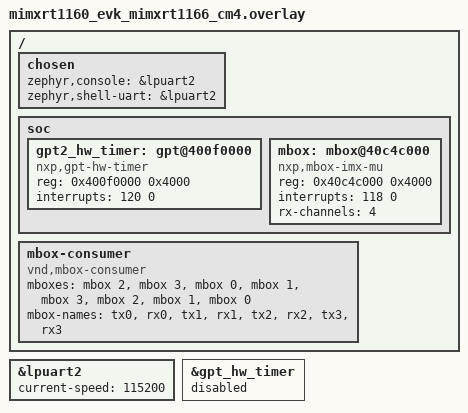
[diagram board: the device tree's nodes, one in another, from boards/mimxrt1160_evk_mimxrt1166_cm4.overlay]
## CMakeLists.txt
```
# Copyright 2024 NXP
#
# SPDX-License-Identifier: Apache-2.0
#

cmake_minimum_required(VERSION 3.28.0)

find_package(Zephyr REQUIRED HINTS $ENV{ZEPHYR_BASE})

project(mbox_data_ipc_remote)

target_sources(app PRIVATE src/main.c)
```

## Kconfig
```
# Copyright 2025 Analog Devices, Inc
#
# SPDX-License-Identifier: Apache-2.0

source "Kconfig.zephyr"

config CHANNELS_TO_TEST
	int "Number of mbox TX/RX channel pairs to test"
	default 4
	help
	  The number of TX/RX channel pairs that should be exercised by
	  this test. This should match the number of pairs set in the
	  devicetree.
```

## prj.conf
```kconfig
CONFIG_STDOUT_CONSOLE=n
CONFIG_MBOX=y
# CONFIG_NO_OPTIMIZATIONS=y
```

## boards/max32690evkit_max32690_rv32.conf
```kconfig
# Copyright (c) 2025 Analog Devices, Inc.
# SPDX-License-Identifier: Apache-2.0

CONFIG_CHANNELS_TO_TEST=1
```

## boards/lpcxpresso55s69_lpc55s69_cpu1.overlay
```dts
/*
 * Copyright 2024 NXP
 *
 * SPDX-License-Identifier: Apache-2.0
 */

/ {
	chosen {
		/* Delete ipc chosen property where old IPM mailbox driver below is
		 * configured.
		 */
		/delete-property/ zephyr,ipc;
	};

	soc {
		/* Delete IPM Driver node nxp,lpc-mailbox */
		/delete-node/ mailbox@8b000;

		/* Attach MBOX driver to Mailbox Unit */
		mbox: mbox@5008b000 {
			compatible = "nxp,mbox-mailbox";
			reg = <0x5008b000 0xec>;
			interrupts = <31 0>;
			rx-channels = <4>;
			#mbox-cells = <1>;
			status = "okay";
		};
	};

	mbox-consumer {
		compatible = "vnd,mbox-consumer";
		mboxes = <&mbox 2>, <&mbox 3>, <&mbox 0>, <&mbox 1>, <&mbox 3>,
			 <&mbox 2>, <&mbox 1>, <&mbox 0>;
		mbox-names = "tx0", "rx0", "tx1", "rx1", "tx2", "rx2", "tx3",
			     "rx3";
	};
};
```

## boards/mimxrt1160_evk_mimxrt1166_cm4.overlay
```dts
/*
 * Copyright 2024 NXP
 *
 * SPDX-License-Identifier: Apache-2.0
 */

/ {
	chosen {
		zephyr,console = &lpuart2;
		zephyr,shell-uart = &lpuart2;

		/* Delete ipc chosen property where old IPM mailbox driver below is
		 * configured.
		 */
		/delete-property/ zephyr,ipc;
	};

	soc {
		/delete-node/ gpt@400f0000;

		/* Replace GPT2 with another GPT kernel timer */
		gpt2_hw_timer: gpt@400f0000 {
			compatible = "nxp,gpt-hw-timer";
			reg = <0x400f0000 0x4000>;
			interrupts = <120 0>;
			status = "okay";
		};

		/* Delete IPM Driver node nxp,imx-mu */
		/delete-node/ mailbox@40c4c000;

		/* Attach MBOX driver to MU Unit */
		mbox: mbox@40c4c000 {
			compatible = "nxp,mbox-imx-mu";
			reg = <0x40c4c000 0x4000>;
			interrupts = <118 0>;
			rx-channels = <4>;
			#mbox-cells = <1>;
			status = "okay";
		};
	};

	mbox-consumer {
		compatible = "vnd,mbox-consumer";
		mboxes = <&mbox 2>, <&mbox 3>, <&mbox 0>, <&mbox 1>, <&mbox 3>,
			 <&mbox 2>, <&mbox 1>, <&mbox 0>;
		mbox-names = "tx0", "rx0", "tx1", "rx1", "tx2", "rx2", "tx3",
			     "rx3";
	};
};

/* Enable secondary LPUART */
&lpuart2 {
	status = "okay";
	current-speed = <115200>;
};

/* Disable primary GPT timer */
&gpt_hw_timer {
	status = "disabled";
};
```

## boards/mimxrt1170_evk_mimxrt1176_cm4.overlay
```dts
/*
 * Copyright 2024 NXP
 *
 * SPDX-License-Identifier: Apache-2.0
 */

/ {
	chosen {
		zephyr,console = &lpuart2;
		zephyr,shell-uart = &lpuart2;

		/* Delete ipc chosen property where old IPM mailbox driver below is
		 * configured.
		 */
		/delete-property/ zephyr,ipc;
	};

	soc {
		/delete-node/ gpt@400f0000;

		/* Replace GPT2 with another GPT kernel timer */
		gpt2_hw_timer: gpt@400f0000 {
			compatible = "nxp,gpt-hw-timer";
			reg = <0x400f0000 0x4000>;
			interrupts = <120 0>;
			status = "okay";
		};

		/* Delete IPM Driver node nxp,imx-mu */
		/delete-node/ mailbox@40c4c000;

		/* Attach MBOX driver to MU Unit */
		mbox: mbox@40c4c000 {
			compatible = "nxp,mbox-imx-mu";
			reg = <0x40c4c000 0x4000>;
			interrupts = <118 0>;
			rx-channels = <4>;
			#mbox-cells = <1>;
			status = "okay";
		};
	};

	mbox-consumer {
		compatible = "vnd,mbox-consumer";
		mboxes = <&mbox 2>, <&mbox 3>, <&mbox 0>, <&mbox 1>, <&mbox 3>,
			 <&mbox 2>, <&mbox 1>, <&mbox 0>;
		mbox-names = "tx0", "rx0", "tx1", "rx1", "tx2", "rx2", "tx3",
			     "rx3";
	};
};

/* Enable secondary LPUART */
&lpuart2 {
	current-speed = <115200>;
	status = "okay";
};

/* Disable primary GPT timer */
&gpt_hw_timer {
	status = "disabled";
};
```

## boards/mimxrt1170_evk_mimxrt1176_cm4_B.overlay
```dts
/*
 * Copyright 2024 NXP
 *
 * SPDX-License-Identifier: Apache-2.0
 */

/ {
	chosen {
		zephyr,console = &lpuart2;
		zephyr,shell-uart = &lpuart2;

		/* Delete ipc chosen property where old IPM mailbox driver below is
		 * configured.
		 */
		/delete-property/ zephyr,ipc;
	};

	soc {
		/delete-node/ gpt@400f0000;

		/* Replace GPT2 with another GPT kernel timer */
		gpt2_hw_timer:gpt@400f0000 {
			compatible = "nxp,gpt-hw-timer";
			reg = <0x400f0000 0x4000>;
			interrupts = <120 0>;
			status = "okay";
		};

		/* Delete IPM Driver node nxp,imx-mu */
		/delete-node/ mailbox@40c4c000;

		/* Attach MBOX driver to MU Unit */
		mbox:mbox@40c4c000 {
			compatible = "nxp,mbox-imx-mu";
			reg = <0x40c4c000 0x4000>;
			interrupts = <118 0>;
			rx-channels = <4>;
			#mbox-cells = <1>;
			status = "okay";
		};
	};

	mbox-consumer {
		compatible = "vnd,mbox-consumer";
		mboxes = <&mbox 2>, <&mbox 3>, <&mbox 0>, <&mbox 1>, <&mbox 3>,
			 <&mbox 2>, <&mbox 1>, <&mbox 0>;
		mbox-names = "tx0", "rx0", "tx1", "rx1", "tx2", "rx2", "tx3",
			     "rx3";
	};
};

/* Enable secondary LPUART */
&lpuart2 {
	status = "okay";
	current-speed = <115200>;
};

/* Disable primary GPT timer */
&gpt_hw_timer {
	status = "disabled";
};
```

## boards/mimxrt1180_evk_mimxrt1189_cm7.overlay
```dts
/*
 * Copyright 2025 NXP
 *
 * SPDX-License-Identifier: Apache-2.0
 */

/ {
	mbox-consumer {
		compatible = "vnd,mbox-consumer";
		mboxes = <&mbox1_b 2>, <&mbox1_b 3>, <&mbox1_b 0>, <&mbox1_b 1>, <&mbox1_b 3>,
			 <&mbox1_b 2>, <&mbox1_b 1>, <&mbox1_b 0>;
		mbox-names = "tx0", "rx0", "tx1", "rx1", "tx2", "rx2", "tx3",
			     "rx3";
	};
};
```

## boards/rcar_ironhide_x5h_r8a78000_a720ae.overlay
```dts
/*
 * Copyright 2026 BayLibre, SAS
 *
 * SPDX-License-Identifier: Apache-2.0
 */

/ {
	mbox-consumer {
		compatible = "vnd,mbox-consumer";
		mboxes = <&mfis 0>, <&mfis 0>,
			 <&mfis 1>, <&mfis 1>,
			 <&mfis 2>, <&mfis 2>,
			 <&mfis 3>, <&mfis 3>;
		mbox-names = "tx0", "rx0",
			     "tx1", "rx1",
			     "tx2", "rx2",
			     "tx3", "rx3";
	};
};
```

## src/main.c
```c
/*
 * Copyright 2024 NXP
 *
 * SPDX-License-Identifier: Apache-2.0
 */

#include <stdio.h>
#include <stdlib.h>
#include <string.h>
#include <zephyr/kernel.h>
#include <zephyr/drivers/mbox.h>

static K_SEM_DEFINE(g_mbox_data_rx_sem, 0, 1);

static uint64_t g_mbox_received_data;
static uint32_t g_mbox_received_channel;

#define TX_CHANNEL_INDEX 0
#define RX_CHANNEL_INDEX 1

#if DT_HAS_COMPAT_STATUS_OKAY(zephyr_mbox_consumer)
#define MBOX_CONSUMER_NODE DT_COMPAT_GET_ANY_STATUS_OKAY(zephyr_mbox_consumer)
#elif DT_HAS_COMPAT_STATUS_OKAY(vnd_mbox_consumer)
#define MBOX_CONSUMER_NODE DT_COMPAT_GET_ANY_STATUS_OKAY(vnd_mbox_consumer)
#else
#error "No zephyr,mbox-consumer or vnd,mbox-consumer node in the devicetree"
#endif

BUILD_ASSERT(DT_PROP_LEN(MBOX_CONSUMER_NODE, mboxes) % 2 == 0,
	     "mboxes must contain tx/rx channel pairs");

#define CHANNELS_TO_TEST (DT_PROP_LEN(MBOX_CONSUMER_NODE, mboxes) / 2)

#if CHANNELS_TO_TEST > 4
#error "The test suite covers at most 4 tx/rx channel pairs"
#endif

#define CHANNEL_ENTRY(_i)                                                                          \
	{                                                                                          \
		MBOX_DT_SPEC_GET(MBOX_CONSUMER_NODE, CONCAT(tx, _i)),                              \
		MBOX_DT_SPEC_GET(MBOX_CONSUMER_NODE, CONCAT(rx, _i)),                              \
	}

static const struct mbox_dt_spec channels[CHANNELS_TO_TEST][2] = {
	CHANNEL_ENTRY(0),
#if CHANNELS_TO_TEST >= 2
	CHANNEL_ENTRY(1),
#endif
#if CHANNELS_TO_TEST >= 3
	CHANNEL_ENTRY(2),
#endif
#if CHANNELS_TO_TEST >= 4
	CHANNEL_ENTRY(3),
#endif
};

static void callback(const struct device *dev, uint32_t channel, void *user_data,
		     struct mbox_msg *data)
{
	if (data != NULL) {
		memcpy(&g_mbox_received_data, data->data, data->size);
		g_mbox_received_channel = channel;
	}

	k_sem_give(&g_mbox_data_rx_sem);
}

int main(void)
{
	struct mbox_msg msg = {0};
	uint64_t message = 0;

	for (int i = 0; i < ARRAY_SIZE(channels); i++) {
		const struct mbox_dt_spec *tx_channel = &channels[i][TX_CHANNEL_INDEX];
		const struct mbox_dt_spec *rx_channel = &channels[i][RX_CHANNEL_INDEX];

		const int max_transfer_size_bytes = mbox_mtu_get_dt(tx_channel);
		/* Sample currently supports only transfer size up to 8 bytes */
		if ((max_transfer_size_bytes <= 0) || (max_transfer_size_bytes > 8)) {
			printk("mbox_mtu_get() error\n");
			return 0;
		}

		if (mbox_register_callback_dt(rx_channel, callback, NULL)) {
			printk("mbox_register_callback() error\n");
			return 0;
		}

		if (mbox_set_enabled_dt(rx_channel, 1)) {
			printk("mbox_set_enable() error\n");
			return 0;
		}

		int test_count = 0;

		while (test_count < 100) {
			test_count++;

			k_sem_take(&g_mbox_data_rx_sem, K_FOREVER);
			message = g_mbox_received_data;

			message++;

			msg.data = &message;
			msg.size = max_transfer_size_bytes;

			if (mbox_send_dt(tx_channel, &msg) < 0) {
				printk("mbox_send() error\n");
				return 0;
			}
		}

		/* Disable current rx channel after channel loop */
		mbox_set_enabled_dt(rx_channel, 0);
	}
}
```
